# R7FA4M3AF register map
Vendor: Renesas Electronics Corporation; Series: RA4; File version: 1.30.03
CPU: CM33 r0p4, little endian, MPU, FPU, VTOR, 4 interrupt priority bits, 96 interrupts
Registers are 8-bit, read-write, reset 0x0 unless marked. A register's access mark holds for its fields unless they carry their own. Offsets are from the block's base; [hi:lo] are bit positions; {n}, {i} and the like mark numbered series; 'fields as' and 'values as' point back to an identical list.

## CAN0 — Controller Area Network 0
Base 0x400A8000
Same registers: CAN1 0x400A9000
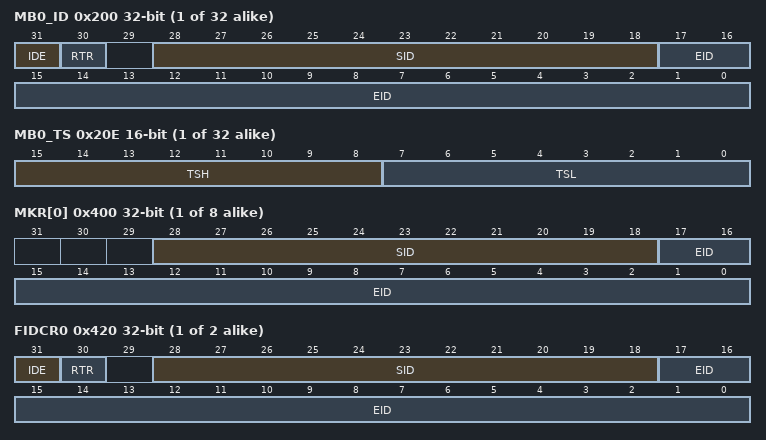
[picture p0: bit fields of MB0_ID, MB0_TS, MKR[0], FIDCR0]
{0x200+0x10*i} MB{i}_ID (i=0..31) 32-bit (reset mask 0x1) — Mailbox ID Register {i}
  [31] IDE — ID Extension
    0=Standard ID; 1=Extended ID
  [30] RTR — Remote Transmission Request
    0=Data frame; 1=Remote frame
  [28:18] SID — Standard ID of data and remote frames
  [17:0] EID — Extended ID of data and remote frames
{0x204+0x10*i} MB{i}_DL (i=0..31) 16-bit reset not defined — Mailbox Data Length Register {i}
  [3:0] DLC — Data Length Code
    0=Data length = 0 byte; 1=Data length = 1 byte; {v}=Data length = {v} bytes (v=2..7); other=Others (Data length = 8 bytes)
{0x206+0x10*i} MB{i}_D0 (i=0..31) reset not defined — Mailbox Data Register {i}
  [7:0] DATA0 — Data Bytes 0
{0x207+0x10*i} MB{i}_D1 (i=0..31) reset not defined — Mailbox Data Register {i}
  [7:0] DATA1 — Data Bytes 1
{0x208+0x10*i} MB{i}_D2 (i=0..31) reset not defined — Mailbox Data Register {i}
  [7:0] DATA2 — Data Bytes 2
{0x209+0x10*i} MB{i}_D3 (i=0..31) reset not defined — Mailbox Data Register {i}
  [7:0] DATA3 — Data Bytes 3
{0x20A+0x10*i} MB{i}_D4 (i=0..31) reset not defined — Mailbox Data Register {i}
  [7:0] DATA4 — Data Bytes 4
{0x20B+0x10*i} MB{i}_D5 (i=0..31) reset not defined — Mailbox Data Register {i}
  [7:0] DATA5 — Data Bytes 5
{0x20C+0x10*i} MB{i}_D6 (i=0..31) reset not defined — Mailbox Data Register {i}
  [7:0] DATA6 — Data Bytes 6
{0x20D+0x10*i} MB{i}_D7 (i=0..31) reset not defined — Mailbox Data Register {i}
  [7:0] DATA7 — Data Bytes 7
{0x20E+0x10*i} MB{i}_TS (i=0..31) 16-bit reset not defined — Mailbox Time Stamp Register {i}
  [15:8] TSH — Time Stamp Higher Byte
  [7:0] TSL — Time Stamp Lower Byte
{0x400+4i} MKR[{i}] (i=0..7) 32-bit reset not defined — Mask Register {i}
  [28:18] SID — Standard ID
    0=Do not compare associated SID[10:0] bits; 1=Compare associated SID[10:0] bits
  [17:0] EID — Extended ID
    0=Do not compare associated EID[17:0] bits; 1=Compare associated EID[17:0] bits
{0x420+4i} FIDCR{i} (i=0..1) 32-bit reset not defined — FIFO Received ID Compare Register {i}
  fields as MB0_ID
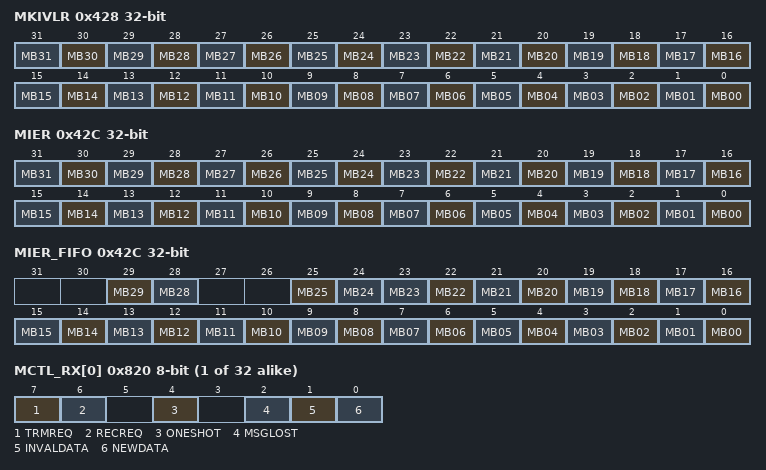
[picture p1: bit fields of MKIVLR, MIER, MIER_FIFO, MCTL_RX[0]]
0x428 MKIVLR 32-bit reset not defined — Mask Invalid Register
  [all] fields
    0=Mask valid; 1=Mask invalid
  [n] MB{n:02} (n=0..31) — Mask Invalid
0x42C MIER 32-bit reset not defined — Mailbox Interrupt Enable Register
  [all] fields
    0=Disable interrupt; 1=Enable interrupt
  [n] MB{n:02} (n=0..31) — Interrupt Enable
0x42C MIER_FIFO 32-bit reset not defined (alternate view of MIER) — Mailbox Interrupt Enable Register for FIFO Mailbox Mode
  [29] MB29 — Receive FIFO Interrupt Generation Timing Control
    0=Generate every time reception completes; 1=Generate when the receive FIFO becomes a buffer warning on reception completion
  [28] MB28 — Receive FIFO Interrupt Enable
    0=Disable interrupt; 1=Enable interrupt
  [25] MB25 — Transmit FIFO Interrupt Generation Timing Control
    0=Generate every time transmission completes; 1=Generate when the transmit FIFO empties on transmission completion
  [24] MB24 — Transmit FIFO Interrupt Enable
    0=Disable interrupt; 1=Enable interrupt
  [n] MB{n:02} (n=0..23) — Interrupt Enable
    0=Disable interrupt; 1=Enable interrupt
{0x820+i} MCTL_RX[{i}] (i=0..31) — Message Control Register for Receive
  [7] TRMREQ — Transmit Mailbox Request
    0=Do not configure for transmission; 1=Configure for transmission
  [6] RECREQ — Receive Mailbox Request
    0=Do not configure for reception; 1=Configure for reception
  [4] ONESHOT — One-Shot Enable
    0=Disable one-shot reception; 1=Enable one-shot reception
  [2] MSGLOST — Message Lost Flag
    0=Message not overwritten or overrun; 1=Message overwritten or overrun
  [1] INVALDATA ro — Reception-in-Progress Status Flag
    0=Message valid; 1=Message being updated
  [0] NEWDATA — Reception Complete Flag
    0=No data received, or 0 was written to the flag; 1=New message being stored or was stored in the mailbox
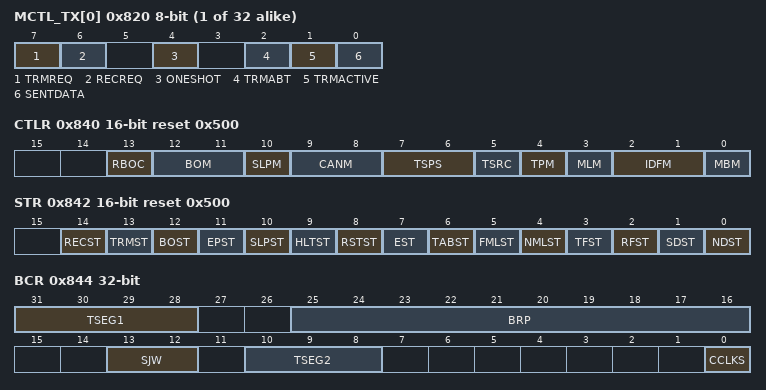
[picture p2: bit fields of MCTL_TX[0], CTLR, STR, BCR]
{0x820+i} MCTL_TX[{i}] (i=0..31) (alternate view of MCTL_RX[{i}]) — Message Control Register for Transmit
  [7] TRMREQ — Transmit Mailbox Request
    values as MCTL_RX[0].TRMREQ
  [6] RECREQ — Receive Mailbox Request
    0=Do not configure for reception; 1=Configure for reception
  [4] ONESHOT — One-Shot Enable
    0=Disable one-shot transmission; 1=Enable one-shot transmission
  [2] TRMABT — Transmission Abort Complete Flag
    0=Transmission started, transmission abort failed because transmission completed, or transmission abort not requested; 1=Transmission abort complete
  [1] TRMACTIVE ro — Transmission-in-Progress Status Flag
    0=Transmission pending or not requested; 1=Transmission in progress
  [0] SENTDATA — Transmission Complete Flag
    0=Transmission not complete; 1=Transmission complete
0x840 CTLR 16-bit reset 0x500 — Control Register
  [13] RBOC — Forcible Return from Bus-Off
    0=No return occurred; 1=Forced return from bus-off state
  [12:11] BOM — Bus-Off Recovery Mode
    0=Normal mode (ISO11898-1-compliant); 1=Enter CAN halt mode automatically on entering bus-off state; 2=Enter CAN halt mode automatically at the end of bus-off state; 3=Enter CAN halt mode during bus-off recovery period through a software request
  [10] SLPM — CAN Sleep Mode
    0=All other modes; 1=CAN sleep mode
  [9:8] CANM — CAN Operating Mode Select
    0=CAN operation mode; 1=CAN reset mode; 2=CAN halt mode; 3=CAN reset mode (forced transition)
  [7:6] TSPS — Time Stamp Prescaler Select
    0=Every 1-bit time; 1=Every 2-bit time; 2=Every 4-bit time; 3=Every 8-bit time
  [5] TSRC — Time Stamp Counter Reset Command
    0=Do not reset time stamp counter; 1=Reset time stamp counter
  [4] TPM — Transmission Priority Mode Select
    0=ID priority transmit mode; 1=Mailbox number priority transmit mode
  [3] MLM — Message Lost Mode Select
    0=Overwrite mode; 1=Overrun mode
  [2:1] IDFM — ID Format Mode Select
    0=Standard ID mode All mailboxes, including FIFO mailboxes, handle only standard IDs; 1=Extended ID mode All mailboxes, including FIFO mailboxes, handle only extended IDs; 2=Mixed ID mode All mailboxes, including FIFO mailboxes, handle both standard and extended IDs. In normal mailbox mode, use the associated IDE bit to differentiate standard and extended IDs. In FIFO mailbox mode, the associated IDE bits are used for mailboxes 0 to 23, the IDE bits in FIDCR0 and FIDCR1 are used for the receive FIFO, and the IDE bit associated with mailbox 24 is used for the transmit FIFO.; 3=Setting prohibited
  [0] MBM — CAN Mailbox Mode Select
    0=Normal mailbox mode; 1=FIFO mailbox mode
0x842 STR 16-bit ro reset 0x500 — Status Register
  [14] RECST — Receive Status Flag
    0=Bus idle or transmission in progress; 1=Reception in progress
  [13] TRMST — Transmit Status Flag
    0=Bus idle or reception in progress; 1=Transmission in progress or module in bus-off state
  [12] BOST — Bus-Off Status Flag
    0=Not in bus-off state; 1=In bus-off state
  [11] EPST — Error-Passive Status Flag
    0=Not in error-passive state; 1=In error-passive state
  [10] SLPST — CAN Sleep Status Flag
    0=Not in CAN sleep mode; 1=In CAN sleep mode
  [9] HLTST — CAN Halt Status Flag
    0=Not in CAN halt mode; 1=In CAN halt mode
  [8] RSTST — CAN Reset Status Flag
    0=Not in CAN reset mode; 1=In CAN reset mode
  [7] EST — Error Status Flag
    0=No error occurred; 1=Error occurred
  [6] TABST — Transmission Abort Status Flag
    0=No mailbox with TRMABT = 1; 1=One or more mailboxes with TRMABT = 1
  [5] FMLST — FIFO Mailbox Message Lost Status Flag
    0=RFMLF = 0; 1=RFMLF = 1
  [4] NMLST — Normal Mailbox Message Lost Status Flag
    0=No mailbox with MSGLOST = 1; 1=One or more mailboxes with MSGLOST = 1
  [3] TFST — Transmit FIFO Status Flag
    0=Transmit FIFO is full; 1=Transmit FIFO is not full
  [2] RFST — Receive FIFO Status Flag
    0=Receive FIFO empty; 1=Message in receive FIFO
  [1] SDST — SENTDATA Status Flag
    0=No mailbox with SENTDATA = 1; 1=One or more mailboxes with SENTDATA = 1
  [0] NDST — NEWDATA Status Flag
    0=No mailbox with NEWDATA = 1; 1=One or more mailboxes with NEWDATA = 1
0x844 BCR 32-bit — Bit Configuration Register
  [31:28] TSEG1 — Time Segment 1 Control
    {v}={v+1} Tq (v=3..15); other=Others (Setting prohibited)
  [25:16] BRP — Baud Rate Prescaler Select
  [13:12] SJW — Synchronization Jump Width Control
    {v}={v+1} Tq (v=0..3)
  [10:8] TSEG2 — Time Segment 2 Control
    0=Setting prohibited; {v}={v+1} Tq (v=1..7)
  [0] CCLKS — CAN Clock Source Selection
    0=PCLKB (generated by the PLL clock); 1=CANMCLK (generated by the main clock oscillator)
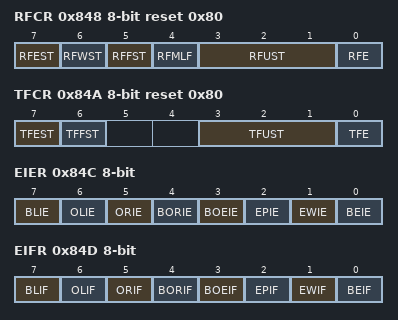
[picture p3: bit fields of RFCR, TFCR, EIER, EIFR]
0x848 RFCR reset 0x80 — Receive FIFO Control Register
  [7] RFEST ro — Receive FIFO Empty Status Flag
    0=Unread message in receive FIFO; 1=No unread message in receive FIFO
  [6] RFWST ro — Receive FIFO Buffer Warning Status Flag
    0=Receive FIFO is not buffer warning; 1=Receive FIFO is buffer warning (3 unread messages)
  [5] RFFST ro — Receive FIFO Full Status Flag
    0=Receive FIFO not full; 1=Receive FIFO full (4 unread messages)
  [4] RFMLF — Receive FIFO Message Lost Flag
    0=Receive FIFO message not lost; 1=Receive FIFO message lost
  [3:1] RFUST ro — Receive FIFO Unread Message Number Status
    0=No unread message; 1=1 unread message; 2=2 unread messages; 3=3 unread messages; 4=4 unread messages
  [0] RFE — Receive FIFO Enable
    0=Disable receive FIFO; 1=Enable receive FIFO
0x849 RFPCR wo reset not defined — Receive FIFO Pointer Control Register
0x84A TFCR reset 0x80 — Transmit FIFO Control Register
  [7] TFEST ro — Transmit FIFO Empty Status
    0=Unsent message in transmit FIFO; 1=No unsent message in transmit FIFO
  [6] TFFST ro — Transmit FIFO Full Status
    0=Transmit FIFO not full; 1=Transmit FIFO full (4 unsent messages)
  [3:1] TFUST ro — Transmit FIFO Unsent Message Number Status
    0=0 unsent messages; 1=1 unsent message; 2=2 unsent messages; 3=3 unread messages; 4=4 unread messages
  [0] TFE — Transmit FIFO Enable
    0=Disable transmit FIFO; 1=Enable transmit FIFO
0x84B TFPCR wo reset not defined — Transmit FIFO Pointer Control Register
0x84C EIER — Error Interrupt Enable Register
  [all] fields
    0=Disable interrupt; 1=Enable interrupt
  [7] BLIE — Bus Lock Interrupt Enable
  [6] OLIE — Overload Frame Transmit Interrupt Enable
  [5] ORIE — Overrun Interrupt Enable
  [4] BORIE — Bus-Off Recovery Interrupt Enable
  [3] BOEIE — Bus-Off Entry Interrupt Enable
  [2] EPIE — Error-Passive Interrupt Enable
  [1] EWIE — Error-Warning Interrupt Enable
  [0] BEIE — Bus Error Interrupt Enable
0x84D EIFR — Error Interrupt Factor Judge Register
  [7] BLIF — Bus Lock Detect Flag
    0=No bus lock detected; 1=Bus lock detected
  [6] OLIF — Overload Frame Transmission Detect Flag
    0=No overload frame transmission detected; 1=Overload frame transmission detected
  [5] ORIF — Receive Overrun Detect Flag
    0=No receive overrun detected; 1=Receive overrun detected
  [4] BORIF — Bus-Off Recovery Detect Flag
    0=No bus-off recovery detected; 1=Bus-off recovery detected
  [3] BOEIF — Bus-Off Entry Detect Flag
    0=No bus-off entry detected; 1=Bus-off entry detected
  [2] EPIF — Error-Passive Detect Flag
    0=No error-passive detected; 1=Error-passive detected
  [1] EWIF — Error-Warning Detect Flag
    0=No error-warning detected; 1=Error-warning detected
  [0] BEIF — Bus Error Detect Flag
    0=No bus error detected; 1=Bus error detected
0x84E RECR ro — Receive Error Count Register
0x84F TECR ro — Transmit Error Count Register
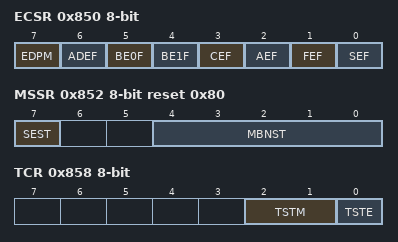
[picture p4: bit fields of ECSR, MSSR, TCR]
0x850 ECSR — Error Code Store Register
  [7] EDPM — Error Display Mode Select
    0=Output first detected error code; 1=Output accumulated error code
  [6] ADEF — ACK Delimiter Error Flag
    0=No ACK delimiter error detected; 1=ACK delimiter error detected
  [5] BE0F — Bit Error (dominant) Flag
    0=No bit error (dominant) detected; 1=Bit error (dominant) detected
  [4] BE1F — Bit Error (recessive) Flag
    0=No bit error (recessive) detected; 1=Bit error (recessive) detected
  [3] CEF — CRC Error Flag
    0=No CRC error detected; 1=CRC error detected
  [2] AEF — ACK Error Flag
    0=No ACK error detected; 1=ACK error detected
  [1] FEF — Form Error Flag
    0=No form error detected; 1=Form error detected
  [0] SEF — Stuff Error Flag
    0=No stuff error detected; 1=Stuff error detected
0x851 CSSR reset not defined — Channel Search Support Register
0x852 MSSR ro reset 0x80 — Mailbox Search Status Register
  [7] SEST — Search Result Status
    0=Search result found; 1=No search result
  [4:0] MBNST — Search Result Mailbox Number Status
0x853 MSMR — Mailbox Search Mode Register
  [1:0] MBSM — Mailbox Search Mode Select
    0=Receive mailbox search mode; 1=Transmit mailbox search mode; 2=Message lost search mode; 3=Channel search mode
0x854 TSR 16-bit ro — Time Stamp Register
0x856 AFSR 16-bit reset not defined — Acceptance Filter Support Register
0x858 TCR — Test Control Register
  [2:1] TSTM — CAN Test Mode Select
    0=Not CAN test mode; 1=Listen-only mode; 2=Self-test mode 0 (external loopback); 3=Self-test mode 1 (internal loopback)
  [0] TSTE — CAN Test Mode Enable
    0=Disable CAN test mode; 1=Enable CAN test mode
